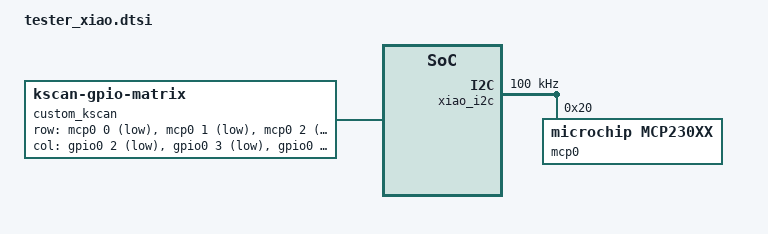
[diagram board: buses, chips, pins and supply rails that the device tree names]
#include <dt-bindings/zmk/matrix_transform.h>

&xiao_i2c {
    status = "okay";
    clock-frequency = <I2C_BITRATE_STANDARD>;

    mcp0: mcp23017@20 {
        compatible = "microchip,mcp230xx";
        status = "okay";
        gpio-controller;
        reg = <0x20>;
        #gpio-cells = <2>;
        ngpios = <16>;
    };
};

/ {
    chosen {
        zmk,kscan = &custom_kscan;
    };

    custom_kscan: kscan_matrix {
        compatible = "zmk,kscan-gpio-matrix";
        diode-direction = "row2col";
        wakeup-source;
        /* Rows = MCP23017 pins (0–15 → GPA0..GPA7, GPB0..GPB7) */
        row-gpios = <&mcp0 0 (GPIO_ACTIVE_LOW | GPIO_PULL_UP)>,
                    <&mcp0 1 (GPIO_ACTIVE_LOW | GPIO_PULL_UP)>,
                    <&mcp0 2 (GPIO_ACTIVE_LOW | GPIO_PULL_UP)>,
                    <&mcp0 3 (GPIO_ACTIVE_LOW | GPIO_PULL_UP)>,
                    <&mcp0 4 (GPIO_ACTIVE_LOW | GPIO_PULL_UP)>,
                    <&mcp0 5 (GPIO_ACTIVE_LOW | GPIO_PULL_UP)>,
                    <&mcp0 6 (GPIO_ACTIVE_LOW | GPIO_PULL_UP)>,
                    <&mcp0 7 (GPIO_ACTIVE_LOW | GPIO_PULL_UP)>,
                    <&mcp0 8 (GPIO_ACTIVE_LOW | GPIO_PULL_UP)>,
                    <&mcp0 9 (GPIO_ACTIVE_LOW | GPIO_PULL_UP)>,
                    <&mcp0 10 (GPIO_ACTIVE_LOW | GPIO_PULL_UP)>,
                    <&mcp0 11 (GPIO_ACTIVE_LOW | GPIO_PULL_UP)>,
                    <&mcp0 12 (GPIO_ACTIVE_LOW | GPIO_PULL_UP)>,
                    <&mcp0 13 (GPIO_ACTIVE_LOW | GPIO_PULL_UP)>,
                    <&mcp0 14 (GPIO_ACTIVE_LOW | GPIO_PULL_UP)>,
                    <&mcp0 15 (GPIO_ACTIVE_LOW | GPIO_PULL_UP)>;


        /* Cols = GPIOs from the XIAO (replace PINx with actual pins used) */
        col-gpios = <&gpio0 2 GPIO_ACTIVE_LOW>,   /* Column 0 */
                    <&gpio0 3 GPIO_ACTIVE_LOW>,  /* Column 1 */
                    <&gpio0 28 GPIO_ACTIVE_LOW>,  /* Column 2 */
                    <&gpio0 29 GPIO_ACTIVE_LOW>,  /* Column 3 */
                    <&gpio0 11 GPIO_ACTIVE_LOW>,  /* Column 4 */
                    <&gpio0 12 GPIO_ACTIVE_LOW>,  /* Column 5 */
                    <&gpio0 13 GPIO_ACTIVE_LOW>,  /* Column 6 */
                    <&gpio0 14 GPIO_ACTIVE_LOW>;  /* Column 7 */

    };
};
